# PIC32MX470F512L register map
Registers are 32-bit, access not given, reset 0x0 unless marked. A register's access mark holds for its fields unless they carry their own. Offsets are from the block's base; [hi:lo] are bit positions; {n}, {i} and the like mark numbered series; 'fields as' and 'values as' point back to an identical list.

## PORTE — PORTE peripheral
Base 0xBF886400
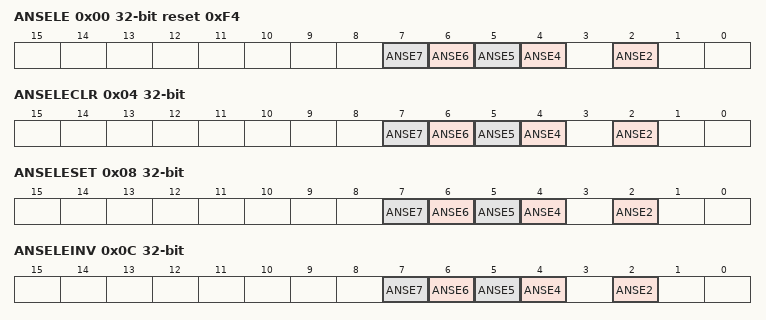
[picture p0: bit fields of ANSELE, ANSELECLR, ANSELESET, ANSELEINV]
0x00 ANSELE reset 0xF4
  [n] ANSE{n} (n=4..7), [2] ANSE2
0x04 ANSELECLR
  [n] ANSE{n} (n=4..7), [2] ANSE2
0x08 ANSELESET
  [n] ANSE{n} (n=4..7), [2] ANSE2
0x0C ANSELEINV
  [n] ANSE{n} (n=4..7), [2] ANSE2
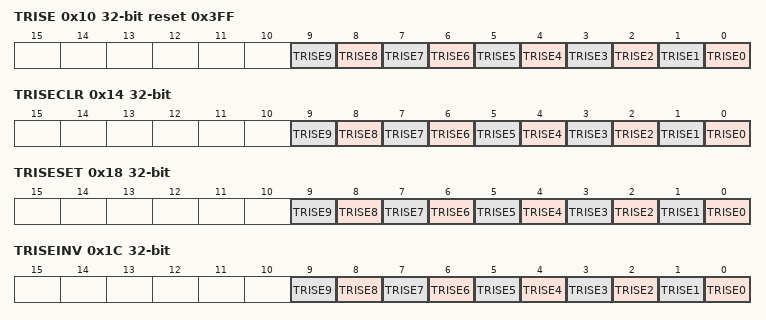
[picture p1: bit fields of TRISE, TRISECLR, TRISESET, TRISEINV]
0x10 TRISE reset 0x3FF
  [n] TRISE{n} (n=0..9)
0x14 TRISECLR
  [n] TRISE{n} (n=0..9)
0x18 TRISESET
  [n] TRISE{n} (n=0..9)
0x1C TRISEINV
  [n] TRISE{n} (n=0..9)
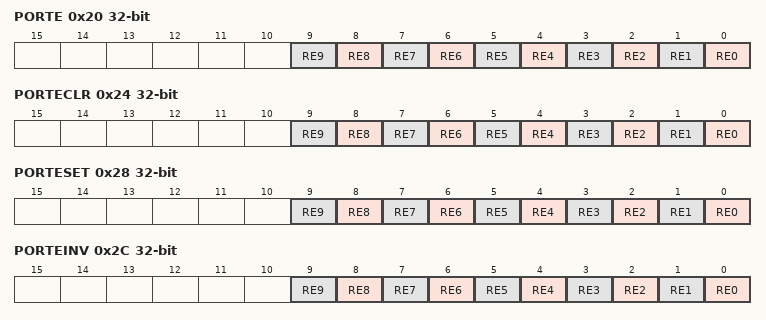
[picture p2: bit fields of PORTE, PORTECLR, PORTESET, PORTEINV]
0x20 PORTE
  [n] RE{n} (n=0..9)
0x24 PORTECLR
  [n] RE{n} (n=0..9)
0x28 PORTESET
  [n] RE{n} (n=0..9)
0x2C PORTEINV
  [n] RE{n} (n=0..9)
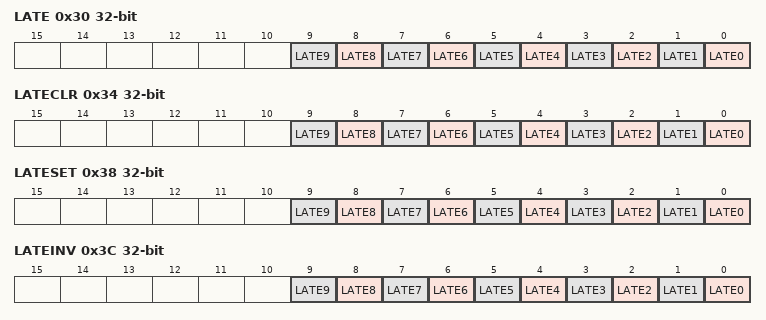
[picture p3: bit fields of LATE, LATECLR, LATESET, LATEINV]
0x30 LATE
  [n] LATE{n} (n=0..9)
0x34 LATECLR
  [n] LATE{n} (n=0..9)
0x38 LATESET
  [n] LATE{n} (n=0..9)
0x3C LATEINV
  [n] LATE{n} (n=0..9)
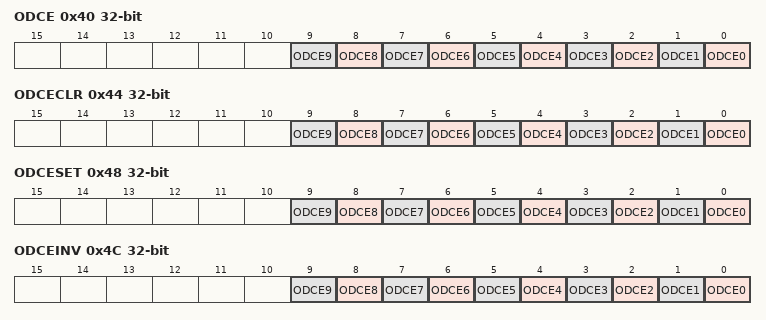
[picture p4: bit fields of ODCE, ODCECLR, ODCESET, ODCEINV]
0x40 ODCE
  [n] ODCE{n} (n=0..9)
0x44 ODCECLR
  [n] ODCE{n} (n=0..9)
0x48 ODCESET
  [n] ODCE{n} (n=0..9)
0x4C ODCEINV
  [n] ODCE{n} (n=0..9)
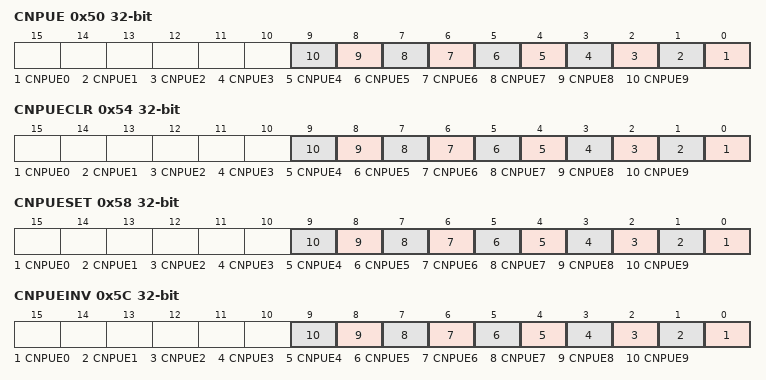
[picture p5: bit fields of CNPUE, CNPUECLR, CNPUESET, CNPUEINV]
0x50 CNPUE
  [n] CNPUE{n} (n=0..9)
0x54 CNPUECLR
  [n] CNPUE{n} (n=0..9)
0x58 CNPUESET
  [n] CNPUE{n} (n=0..9)
0x5C CNPUEINV
  [n] CNPUE{n} (n=0..9)
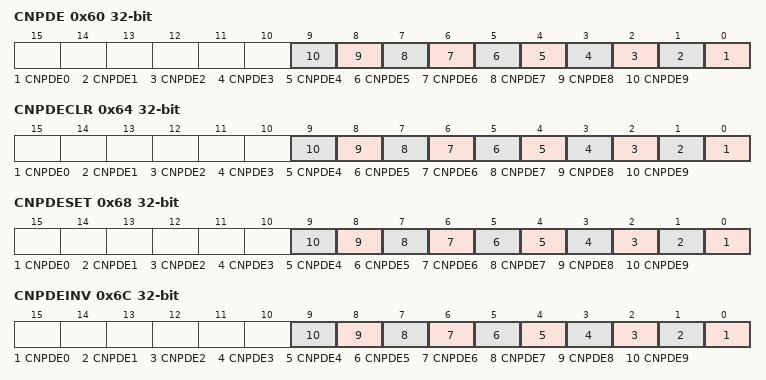
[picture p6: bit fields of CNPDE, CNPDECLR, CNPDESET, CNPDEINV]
0x60 CNPDE
  [n] CNPDE{n} (n=0..9)
0x64 CNPDECLR
  [n] CNPDE{n} (n=0..9)
0x68 CNPDESET
  [n] CNPDE{n} (n=0..9)
0x6C CNPDEINV
  [n] CNPDE{n} (n=0..9)
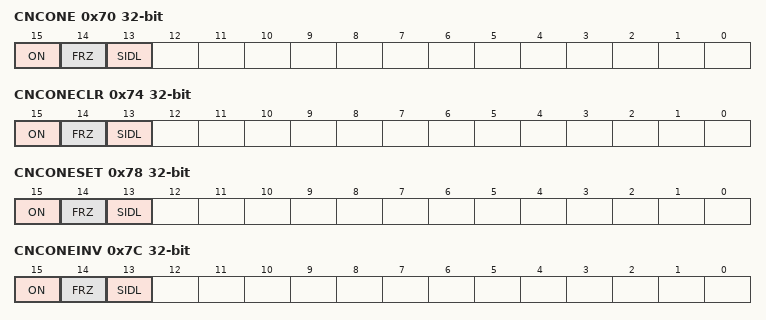
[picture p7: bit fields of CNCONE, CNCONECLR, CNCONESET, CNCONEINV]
0x70 CNCONE
  [15] ON, [14] FRZ, [13] SIDL
0x74 CNCONECLR
  [15] ON, [14] FRZ, [13] SIDL
0x78 CNCONESET
  [15] ON, [14] FRZ, [13] SIDL
0x7C CNCONEINV
  [15] ON, [14] FRZ, [13] SIDL
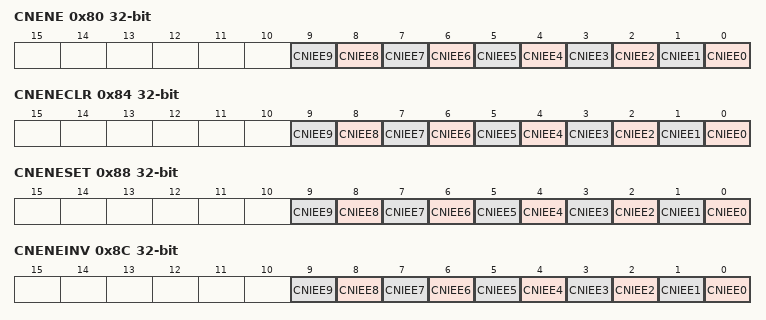
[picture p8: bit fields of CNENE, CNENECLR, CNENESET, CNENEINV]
0x80 CNENE
  [n] CNIEE{n} (n=0..9)
0x84 CNENECLR
  [n] CNIEE{n} (n=0..9)
0x88 CNENESET
  [n] CNIEE{n} (n=0..9)
0x8C CNENEINV
  [n] CNIEE{n} (n=0..9)
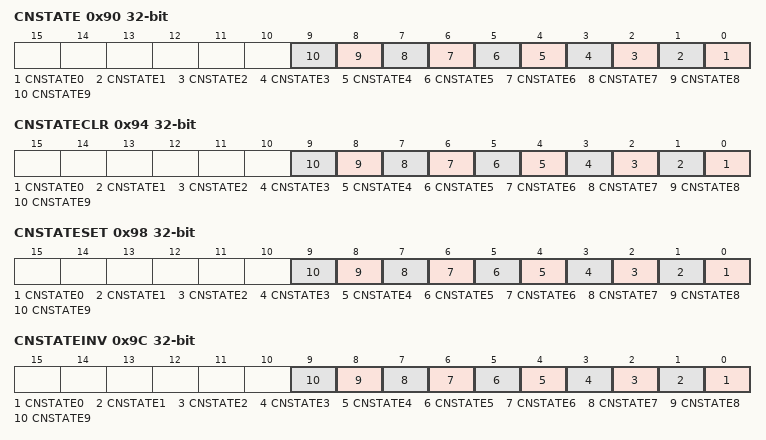
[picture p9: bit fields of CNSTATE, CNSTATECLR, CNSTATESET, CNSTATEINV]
0x90 CNSTATE
  [n] CNSTATE{n} (n=0..9)
0x94 CNSTATECLR
  [n] CNSTATE{n} (n=0..9)
0x98 CNSTATESET
  [n] CNSTATE{n} (n=0..9)
0x9C CNSTATEINV
  [n] CNSTATE{n} (n=0..9)

## PORTF — PORTF peripheral
Base 0xBF886500
0x00 ANSELF
0x04 ANSELFCLR
0x08 ANSELFSET
0x0C ANSELFINV
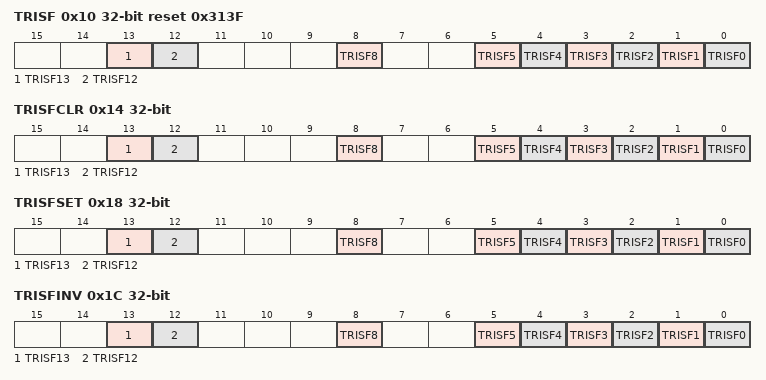
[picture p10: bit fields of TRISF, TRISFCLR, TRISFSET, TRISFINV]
0x10 TRISF reset 0x313F
  [13] TRISF13, [12] TRISF12, [8] TRISF8, [n] TRISF{n} (n=0..5)
0x14 TRISFCLR
  [13] TRISF13, [12] TRISF12, [8] TRISF8, [n] TRISF{n} (n=0..5)
0x18 TRISFSET
  [13] TRISF13, [12] TRISF12, [8] TRISF8, [n] TRISF{n} (n=0..5)
0x1C TRISFINV
  [13] TRISF13, [12] TRISF12, [8] TRISF8, [n] TRISF{n} (n=0..5)
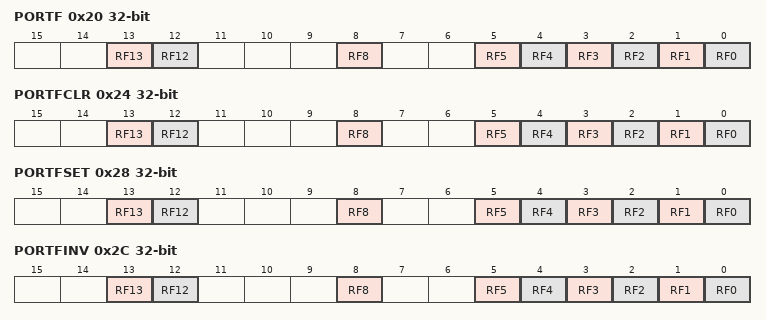
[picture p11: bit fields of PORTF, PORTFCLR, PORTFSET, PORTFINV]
0x20 PORTF
  [13] RF13, [12] RF12, [8] RF8, [n] RF{n} (n=0..5)
0x24 PORTFCLR
  [13] RF13, [12] RF12, [8] RF8, [n] RF{n} (n=0..5)
0x28 PORTFSET
  [13] RF13, [12] RF12, [8] RF8, [n] RF{n} (n=0..5)
0x2C PORTFINV
  [13] RF13, [12] RF12, [8] RF8, [n] RF{n} (n=0..5)
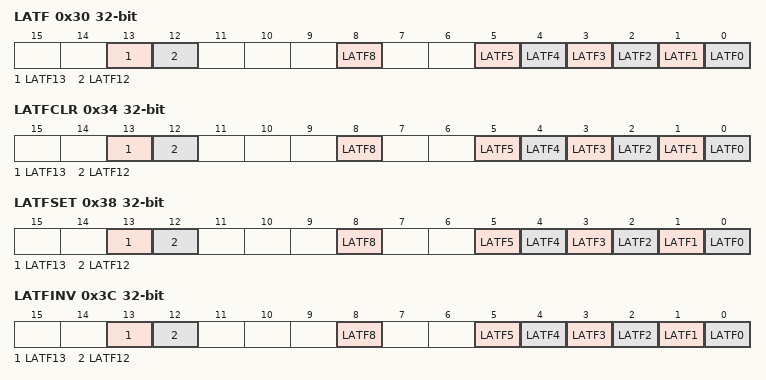
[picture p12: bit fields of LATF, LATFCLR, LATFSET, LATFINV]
0x30 LATF
  [13] LATF13, [12] LATF12, [8] LATF8, [n] LATF{n} (n=0..5)
0x34 LATFCLR
  [13] LATF13, [12] LATF12, [8] LATF8, [n] LATF{n} (n=0..5)
0x38 LATFSET
  [13] LATF13, [12] LATF12, [8] LATF8, [n] LATF{n} (n=0..5)
0x3C LATFINV
  [13] LATF13, [12] LATF12, [8] LATF8, [n] LATF{n} (n=0..5)
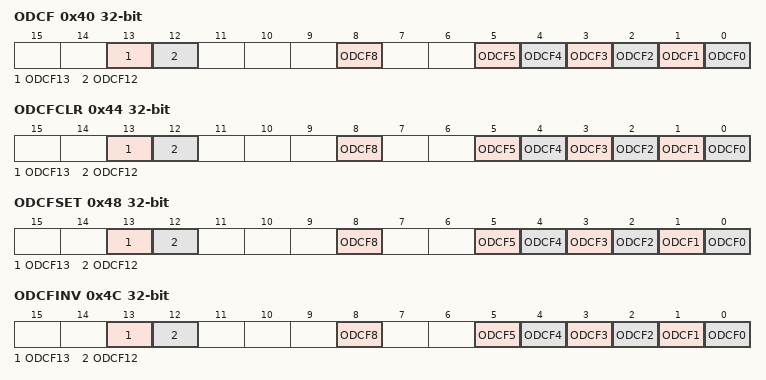
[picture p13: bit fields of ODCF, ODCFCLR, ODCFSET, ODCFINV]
0x40 ODCF
  [13] ODCF13, [12] ODCF12, [8] ODCF8, [n] ODCF{n} (n=0..5)
0x44 ODCFCLR
  [13] ODCF13, [12] ODCF12, [8] ODCF8, [n] ODCF{n} (n=0..5)
0x48 ODCFSET
  [13] ODCF13, [12] ODCF12, [8] ODCF8, [n] ODCF{n} (n=0..5)
0x4C ODCFINV
  [13] ODCF13, [12] ODCF12, [8] ODCF8, [n] ODCF{n} (n=0..5)
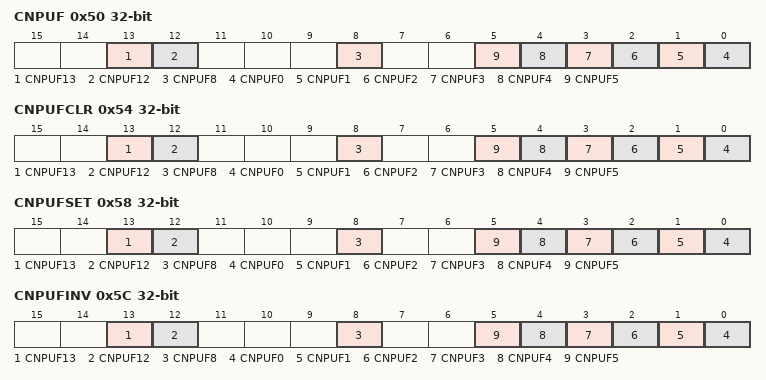
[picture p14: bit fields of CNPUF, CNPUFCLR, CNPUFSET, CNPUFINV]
0x50 CNPUF
  [13] CNPUF13, [12] CNPUF12, [8] CNPUF8, [n] CNPUF{n} (n=0..5)
0x54 CNPUFCLR
  [13] CNPUF13, [12] CNPUF12, [8] CNPUF8, [n] CNPUF{n} (n=0..5)
0x58 CNPUFSET
  [13] CNPUF13, [12] CNPUF12, [8] CNPUF8, [n] CNPUF{n} (n=0..5)
0x5C CNPUFINV
  [13] CNPUF13, [12] CNPUF12, [8] CNPUF8, [n] CNPUF{n} (n=0..5)
0x60 CNPDF
  [13] CNPDF13, [12] CNPDF12, [8] CNPDF8, [n] CNPDF{n} (n=0..5)
0x64 CNPDFCLR
  [13] CNPDF13, [12] CNPDF12, [8] CNPDF8, [n] CNPDF{n} (n=0..5)
0x68 CNPDFSET
  [13] CNPDF13, [12] CNPDF12, [8] CNPDF8, [n] CNPDF{n} (n=0..5)
0x6C CNPDFINV
  [13] CNPDF13, [12] CNPDF12, [8] CNPDF8, [n] CNPDF{n} (n=0..5)
0x70 CNCONF
  [15] ON, [14] FRZ, [13] SIDL
0x74 CNCONFCLR
  [15] ON, [14] FRZ, [13] SIDL
0x78 CNCONFSET
  [15] ON, [14] FRZ, [13] SIDL
0x7C CNCONFINV
  [15] ON, [14] FRZ, [13] SIDL
0x80 CNENF
  [13] CNIEF13, [12] CNIEF12, [8] CNIEF8, [n] CNIEF{n} (n=0..5)
0x84 CNENFCLR
  [13] CNIEF13, [12] CNIEF12, [8] CNIEF8, [n] CNIEF{n} (n=0..5)
0x88 CNENFSET
  [13] CNIEF13, [12] CNIEF12, [8] CNIEF8, [n] CNIEF{n} (n=0..5)
0x8C CNENFINV
  [13] CNIEF13, [12] CNIEF12, [8] CNIEF8, [n] CNIEF{n} (n=0..5)
0x90 CNSTATF
  [13] CNSTATF13, [12] CNSTATF12, [8] CNSTATF8, [n] CNSTATF{n} (n=0..5)
0x94 CNSTATFCLR
  fields as CNSTATF
0x98 CNSTATFSET
  fields as CNSTATF
0x9C CNSTATFINV
  fields as CNSTATF
